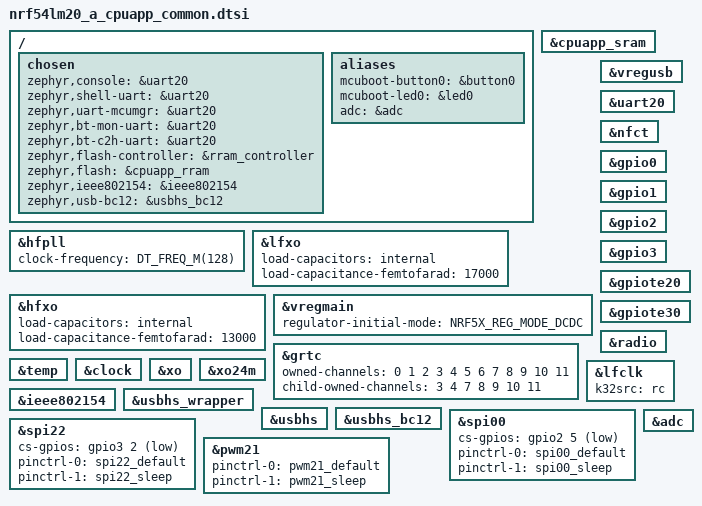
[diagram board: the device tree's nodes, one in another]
/*
 * Copyright (c) 2025 Nordic Semiconductor ASA
 *
 * SPDX-License-Identifier: Apache-2.0
 */

/* This file is common to the secure and non-secure domain */

#include <nordic/nrf54lm20_a_b_cpuapp.dtsi>
#include "ophelia5dk_common.dtsi"

/ {
	chosen {
		zephyr,console = &uart20;
		zephyr,shell-uart = &uart20;
		zephyr,uart-mcumgr = &uart20;
		zephyr,bt-mon-uart = &uart20;
		zephyr,bt-c2h-uart = &uart20;
		zephyr,flash-controller = &rram_controller;
		zephyr,flash = &cpuapp_rram;
		zephyr,ieee802154 = &ieee802154;
		zephyr,usb-bc12 = &usbhs_bc12;
	};

	aliases {
		mcuboot-button0 = &button0;
		mcuboot-led0 = &led0;
		adc = &adc;
	};
};

&cpuapp_sram {
	status = "okay";
};

&hfpll {
	clock-frequency = <DT_FREQ_M(128)>;
};

&lfxo {
	load-capacitors = "internal";
	load-capacitance-femtofarad = <17000>;
};

&hfxo {
	load-capacitors = "internal";
	load-capacitance-femtofarad = <13000>;
};

&vregmain {
	status = "okay";
	regulator-initial-mode = <NRF5X_REG_MODE_DCDC>;
};

&vregusb {
	status = "okay";
};

&grtc {
	owned-channels = <0 1 2 3 4 5 6 7 8 9 10 11>;
	/* Channels 7-11 reserved for Zero Latency IRQs, 3-4 for FLPR */
	child-owned-channels = <3 4 7 8 9 10 11>;
	status = "okay";
};

&uart20 {
	status = "okay";
};

&nfct {
	status = "okay";
};

&gpio0 {
	status = "okay";
};

&gpio1 {
	status = "okay";
};

&gpio2 {
	status = "okay";
};

&gpio3 {
	status = "okay";
};

&gpiote20 {
	status = "okay";
};

&gpiote30 {
	status = "okay";
};

&radio {
	status = "okay";
};

temp_sensor: &temp {
	status = "okay";
};

&clock {
	status = "okay";
};

&xo {
	status = "okay";
};

&lfclk {
	status = "okay";
	k32src = "rc";   /* selects the internal RC oscillator as LFCLK source */
};

&xo24m {
	status = "okay";
};

&ieee802154 {
	status = "okay";
};

&usbhs_wrapper {
	status = "okay";
};

zephyr_udc0: &usbhs {
	status = "okay";
};

zephyr_uhc0: &usbhs {
	status = "okay";
};

&usbhs_bc12 {
	status = "okay";
};

&spi00 {
	status = "okay";
	cs-gpios = <&gpio2 5 GPIO_ACTIVE_LOW>;
	pinctrl-0 = <&spi00_default>;
	pinctrl-1 = <&spi00_sleep>;
	pinctrl-names = "default", "sleep";
};

&adc {
	status = "okay";
};

/*
 * Note this SPI instance conflicts with UART30. Disable or reconfigure pinctrl for UART30
 * to use this SPI instance.
 */
nordic_expansion_spi: &spi22 {
	cs-gpios = <&gpio3 2 GPIO_ACTIVE_LOW>;
	pinctrl-0 = <&spi22_default>;
	pinctrl-1 = <&spi22_sleep>;
	pinctrl-names = "default", "sleep";
};

nordic_expansion_pwm: &pwm21 {
	pinctrl-0 = <&pwm21_default>;
	pinctrl-1 = <&pwm21_sleep>;
	pinctrl-names = "default", "sleep";
};
